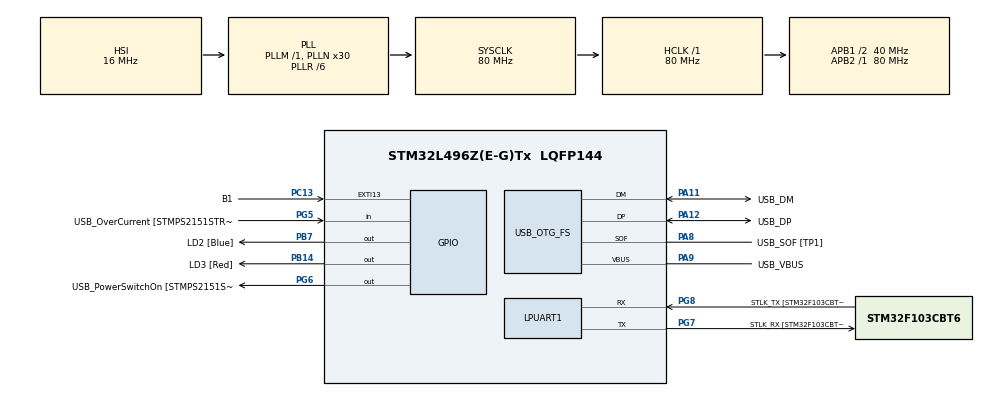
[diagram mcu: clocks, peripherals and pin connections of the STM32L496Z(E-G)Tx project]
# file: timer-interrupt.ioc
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Mcu.Family=STM32L4
PG8.Mode=Asynchronous
RCC.CortexFreq_Value=80000000
PG6.Signal=GPIO_Output
PG8.Signal=LPUART1_RX
PB14.GPIO_Label=LD3 [Red]
PG6.GPIO_Label=USB_PowerSwitchOn [STMPS2151STR_EN]
RCC.SYSCLKSourceVirtual=RCC_SYSCLKSOURCE_PLLCLK
PA11.Mode=Device_Only
PC15-OSC32_OUT\ (PC15).Mode=LSE-External-Oscillator
PC13.GPIO_Label=B1
PG5.GPIO_Label=USB_OverCurrent [STMPS2151STR_FAULT]
RCC.SYSCLKSource=RCC_SYSCLKSOURCE_PLLCLK
ProjectManager.StackSize=0x400
PC14-OSC32_IN\ (PC14).Mode=LSE-External-Oscillator
PA14\ (JTCK/SWCLK).Signal=SYS_JTCK-SWCLK
PA12.Signal=USB_OTG_FS_DP
RCC.HCLKFreq_Value=80000000
RCC.APB2TimFreq_Value=80000000
TIM2.ClockDivision=TIM_CLOCKDIVISION_DIV2
RCC.AHBFreq_Value=80000000
RCC.HSE_VALUE=8000000
RCC.PLLMUL=RCC_PLL_MUL9
PA13\ (JTMS/SWDIO).GPIO_Label=TMS
NVIC.TIM2_IRQn=true\:0\:0\:false\:false\:true\:true\:true
PA10.GPIO_Label=USB_ID
PB7.Signal=GPIO_Output
PA8.Signal=USB_OTG_FS_SOF
PA14\ (JTCK/SWCLK).Mode=Trace_Asynchronous_SW
PB7.GPIO_Label=LD2 [Blue]
Mcu.Package=LQFP144
TIM2.Prescaler=39999
PA10.Signal=USB_OTG_FS_ID
USB_OTG_FS.VirtualMode=Device_Only
PA14\ (JTCK/SWCLK).GPIO_Label=TCK
RCC.PLLSourceVirtualString=RCC_PLLSOURCE_HSI
RCC.APB1TimFreq_Value=80000000
RCC.HSI48_VALUE=48000000
RCC.PLLSAI1N=24
PB3\ (JTDO/TRACESWO).GPIO_Label=SWO
RCC.MSI_VALUE=4000000
PG7.Signal=LPUART1_TX
PA13\ (JTMS/SWDIO).Mode=Trace_Asynchronous_SW
TIM2.CounterMode=TIM_COUNTERMODE_DOWN
PG5.Signal=GPIO_Input
PC13.Signal=GPXTI13
PA9.GPIO_Label=USB_VBUS
PA11.GPIO_Label=USB_DM
PC15-OSC32_OUT\ (PC15).Signal=RCC_OSC32_OUT
RCC.APB1CLKDivider=RCC_HCLK_DIV2
PA12.GPIO_Label=USB_DP
PH1-OSC_OUT\ (PH1).Signal=RCC_OSC_OUT
PG8.GPIO_Label=STLK_TX [STM32F103CBT6_PA2]
PA9.Mode=Activate_VBUS
PA8.GPIO_Label=USB_SOF [TP1]
PB3\ (JTDO/TRACESWO).Signal=SYS_JTDO-SWO
ProjectManager.TargetToolchain=STM32CubeIDE
PA9.Signal=USB_OTG_FS_VBUS
RCC.USBFreq_Value=192000000
PG7.Mode=Asynchronous
PB14.Signal=GPIO_Output
board=NUCLEO-L496ZG
RCC.VCOOutputFreq_Value=480000000
RCC.APB2Freq_Value=80000000
RCC.PRESCALERUSB=RCC_USBCLKSOURCE_PLL_DIV1_5
VP_TIM2_VS_ClockSourceINT.Mode=Internal
PG7.GPIO_Label=STLK_RX [STM32F103CBT6_PA3]
RCC.ADCFreq_Value=192000000
TIM2.Period=1999
Mcu.Name=STM32L496Z(E-G)Tx
RCC.48MHZClocksFreq_Value=24000000
RCC.SYSCLKFreq_VALUE=80000000
PA12.Mode=Device_Only
PC14-OSC32_IN\ (PC14).Signal=RCC_OSC32_IN
PA11.Signal=USB_OTG_FS_DM
ProjectManager.HeapSize=0x200
RCC.HSI_VALUE=16000000
NVIC.PriorityGroup=NVIC_PRIORITYGROUP_4
RCC.PLLR=RCC_PLLR_DIV6
RCC.PLLN=30
PB3\ (JTDO/TRACESWO).Mode=Trace_Asynchronous_SW
TIM2.AutoReloadPreload=TIM_AUTORELOAD_PRELOAD_ENABLE
PA8.Mode=Activate_SOF_FS
RCC.APB1Freq_Value=40000000
PA13\ (JTMS/SWDIO).Signal=SYS_JTMS-SWDIO

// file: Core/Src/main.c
/* USER CODE BEGIN Header */
/**
  ******************************************************************************
  * @file           : main.c
  * @brief          : Main program body
  ******************************************************************************
  * @attention
  *
  * <h2><center>&copy; Copyright (c) 2021 STMicroelectronics.
  * All rights reserved.</center></h2>
  *
  * This software component is licensed by ST under BSD 3-Clause license,
  * the "License"; You may not use this file except in compliance with the
  * License. You may obtain a copy of the License at:
  *                        opensource.org/licenses/BSD-3-Clause
  *
  ******************************************************************************
  */
/* USER CODE END Header */
#include "main.h"

UART_HandleTypeDef hlpuart1;

TIM_HandleTypeDef htim2;

PCD_HandleTypeDef hpcd_USB_OTG_FS;

void SystemClock_Config(void);
static void MX_GPIO_Init(void);
static void MX_LPUART1_UART_Init(void);
static void MX_USB_OTG_FS_PCD_Init(void);
static void MX_TIM2_Init(void);

/* USER CODE BEGIN 0 */
void HAL_TIM_PeriodElapsedCallback(TIM_HandleTypeDef *htim)
{
    HAL_GPIO_TogglePin(GPIOB, LD2_Pin);
}
/* USER CODE END 0 */

int main(void)
{

  /* MCU Configuration--------------------------------------------------------*/

  /* Reset of all peripherals, Initializes the Flash interface and the Systick. */
  HAL_Init();

  /* Configure the system clock */
  SystemClock_Config();

  /* Initialize all configured peripherals */
  MX_GPIO_Init();
  MX_LPUART1_UART_Init();
  MX_USB_OTG_FS_PCD_Init();
  MX_TIM2_Init();

  /* USER CODE BEGIN 2 */
  HAL_TIM_Base_Start_IT(&htim2); // Enable the timer
  /* USER CODE END 2 */

  /* Infinite loop */
  while (1)
  {

  }
}

void SystemClock_Config(void)
{
  RCC_OscInitTypeDef RCC_OscInitStruct = {0};
  RCC_ClkInitTypeDef RCC_ClkInitStruct = {0};
  RCC_PeriphCLKInitTypeDef PeriphClkInit = {0};

  /** Initializes the RCC Oscillators according to the specified parameters
  * in the RCC_OscInitTypeDef structure.
  */
  RCC_OscInitStruct.OscillatorType = RCC_OSCILLATORTYPE_HSI;
  RCC_OscInitStruct.HSIState = RCC_HSI_ON;
  RCC_OscInitStruct.HSICalibrationValue = RCC_HSICALIBRATION_DEFAULT;
  RCC_OscInitStruct.PLL.PLLState = RCC_PLL_ON;
  RCC_OscInitStruct.PLL.PLLSource = RCC_PLLSOURCE_HSI;
  RCC_OscInitStruct.PLL.PLLM = 1;
  RCC_OscInitStruct.PLL.PLLN = 30;
  RCC_OscInitStruct.PLL.PLLP = RCC_PLLP_DIV2;
  RCC_OscInitStruct.PLL.PLLQ = RCC_PLLQ_DIV2;
  RCC_OscInitStruct.PLL.PLLR = RCC_PLLR_DIV6;
  if (HAL_RCC_OscConfig(&RCC_OscInitStruct) != HAL_OK)
  {
    Error_Handler();
  }
  /** Initializes the CPU, AHB and APB buses clocks
  */
  RCC_ClkInitStruct.ClockType = RCC_CLOCKTYPE_HCLK|RCC_CLOCKTYPE_SYSCLK
                              |RCC_CLOCKTYPE_PCLK1|RCC_CLOCKTYPE_PCLK2;
  RCC_ClkInitStruct.SYSCLKSource = RCC_SYSCLKSOURCE_PLLCLK;
  RCC_ClkInitStruct.AHBCLKDivider = RCC_SYSCLK_DIV1;
  RCC_ClkInitStruct.APB1CLKDivider = RCC_HCLK_DIV2;
  RCC_ClkInitStruct.APB2CLKDivider = RCC_HCLK_DIV1;

  if (HAL_RCC_ClockConfig(&RCC_ClkInitStruct, FLASH_LATENCY_4) != HAL_OK)
  {
    Error_Handler();
  }
  PeriphClkInit.PeriphClockSelection = RCC_PERIPHCLK_LPUART1|RCC_PERIPHCLK_USB;
  PeriphClkInit.Lpuart1ClockSelection = RCC_LPUART1CLKSOURCE_PCLK1;
  PeriphClkInit.UsbClockSelection = RCC_USBCLKSOURCE_PLLSAI1;
  PeriphClkInit.PLLSAI1.PLLSAI1Source = RCC_PLLSOURCE_HSI;
  PeriphClkInit.PLLSAI1.PLLSAI1M = 1;
  PeriphClkInit.PLLSAI1.PLLSAI1N = 24;
  PeriphClkInit.PLLSAI1.PLLSAI1P = RCC_PLLP_DIV2;
  PeriphClkInit.PLLSAI1.PLLSAI1Q = RCC_PLLQ_DIV2;
  PeriphClkInit.PLLSAI1.PLLSAI1R = RCC_PLLR_DIV2;
  PeriphClkInit.PLLSAI1.PLLSAI1ClockOut = RCC_PLLSAI1_48M2CLK;
  if (HAL_RCCEx_PeriphCLKConfig(&PeriphClkInit) != HAL_OK)
  {
    Error_Handler();
  }
  /** Configure the main internal regulator output voltage
  */
  if (HAL_PWREx_ControlVoltageScaling(PWR_REGULATOR_VOLTAGE_SCALE1) != HAL_OK)
  {
    Error_Handler();
  }
}

static void MX_LPUART1_UART_Init(void)
{

  hlpuart1.Instance = LPUART1;
  hlpuart1.Init.BaudRate = 209700;
  hlpuart1.Init.WordLength = UART_WORDLENGTH_7B;
  hlpuart1.Init.StopBits = UART_STOPBITS_1;
  hlpuart1.Init.Parity = UART_PARITY_NONE;
  hlpuart1.Init.Mode = UART_MODE_TX_RX;
  hlpuart1.Init.HwFlowCtl = UART_HWCONTROL_NONE;
  hlpuart1.Init.OneBitSampling = UART_ONE_BIT_SAMPLE_DISABLE;
  hlpuart1.AdvancedInit.AdvFeatureInit = UART_ADVFEATURE_NO_INIT;
  if (HAL_UART_Init(&hlpuart1) != HAL_OK)
  {
    Error_Handler();
  }

}

static void MX_TIM2_Init(void)
{

  TIM_ClockConfigTypeDef sClockSourceConfig = {0};
  TIM_MasterConfigTypeDef sMasterConfig = {0};

  htim2.Instance = TIM2;
  htim2.Init.Prescaler = 39999;
  htim2.Init.CounterMode = TIM_COUNTERMODE_DOWN;
  htim2.Init.Period = 1999;
  htim2.Init.ClockDivision = TIM_CLOCKDIVISION_DIV2;
  htim2.Init.AutoReloadPreload = TIM_AUTORELOAD_PRELOAD_ENABLE;
  if (HAL_TIM_Base_Init(&htim2) != HAL_OK)
  {
    Error_Handler();
  }
  sClockSourceConfig.ClockSource = TIM_CLOCKSOURCE_INTERNAL;
  if (HAL_TIM_ConfigClockSource(&htim2, &sClockSourceConfig) != HAL_OK)
  {
    Error_Handler();
  }
  sMasterConfig.MasterOutputTrigger = TIM_TRGO_RESET;
  sMasterConfig.MasterSlaveMode = TIM_MASTERSLAVEMODE_DISABLE;
  if (HAL_TIMEx_MasterConfigSynchronization(&htim2, &sMasterConfig) != HAL_OK)
  {
    Error_Handler();
  }

}

static void MX_USB_OTG_FS_PCD_Init(void)
{

  hpcd_USB_OTG_FS.Instance = USB_OTG_FS;
  hpcd_USB_OTG_FS.Init.dev_endpoints = 6;
  hpcd_USB_OTG_FS.Init.speed = PCD_SPEED_FULL;
  hpcd_USB_OTG_FS.Init.phy_itface = PCD_PHY_EMBEDDED;
  hpcd_USB_OTG_FS.Init.Sof_enable = ENABLE;
  hpcd_USB_OTG_FS.Init.low_power_enable = DISABLE;
  hpcd_USB_OTG_FS.Init.lpm_enable = DISABLE;
  hpcd_USB_OTG_FS.Init.battery_charging_enable = ENABLE;
  hpcd_USB_OTG_FS.Init.use_dedicated_ep1 = DISABLE;
  hpcd_USB_OTG_FS.Init.vbus_sensing_enable = ENABLE;
  if (HAL_PCD_Init(&hpcd_USB_OTG_FS) != HAL_OK)
  {
    Error_Handler();
  }

}

static void MX_GPIO_Init(void)
{
  GPIO_InitTypeDef GPIO_InitStruct = {0};

  /* GPIO Ports Clock Enable */
  __HAL_RCC_GPIOC_CLK_ENABLE();
  __HAL_RCC_GPIOH_CLK_ENABLE();
  __HAL_RCC_GPIOB_CLK_ENABLE();
  __HAL_RCC_GPIOG_CLK_ENABLE();
  HAL_PWREx_EnableVddIO2();
  __HAL_RCC_GPIOA_CLK_ENABLE();

  /*Configure GPIO pin Output Level */
  HAL_GPIO_WritePin(GPIOB, LD3_Pin|LD2_Pin, GPIO_PIN_RESET);

  /*Configure GPIO pin Output Level */
  HAL_GPIO_WritePin(USB_PowerSwitchOn_GPIO_Port, USB_PowerSwitchOn_Pin, GPIO_PIN_RESET);

  /*Configure GPIO pin : B1_Pin */
  GPIO_InitStruct.Pin = B1_Pin;
  GPIO_InitStruct.Mode = GPIO_MODE_IT_RISING;
  GPIO_InitStruct.Pull = GPIO_NOPULL;
  HAL_GPIO_Init(B1_GPIO_Port, &GPIO_InitStruct);

  /*Configure GPIO pins : LD3_Pin LD2_Pin */
  GPIO_InitStruct.Pin = LD3_Pin|LD2_Pin;
  GPIO_InitStruct.Mode = GPIO_MODE_OUTPUT_PP;
  GPIO_InitStruct.Pull = GPIO_NOPULL;
  GPIO_InitStruct.Speed = GPIO_SPEED_FREQ_LOW;
  HAL_GPIO_Init(GPIOB, &GPIO_InitStruct);

  /*Configure GPIO pin : USB_OverCurrent_Pin */
  GPIO_InitStruct.Pin = USB_OverCurrent_Pin;
  GPIO_InitStruct.Mode = GPIO_MODE_INPUT;
  GPIO_InitStruct.Pull = GPIO_NOPULL;
  HAL_GPIO_Init(USB_OverCurrent_GPIO_Port, &GPIO_InitStruct);

  /*Configure GPIO pin : USB_PowerSwitchOn_Pin */
  GPIO_InitStruct.Pin = USB_PowerSwitchOn_Pin;
  GPIO_InitStruct.Mode = GPIO_MODE_OUTPUT_PP;
  GPIO_InitStruct.Pull = GPIO_NOPULL;
  GPIO_InitStruct.Speed = GPIO_SPEED_FREQ_LOW;
  HAL_GPIO_Init(USB_PowerSwitchOn_GPIO_Port, &GPIO_InitStruct);

}

void Error_Handler(void)
{
  __disable_irq();
  while (1)
  {
  }
}

/************************ (C) COPYRIGHT STMicroelectronics *****END OF FILE****/
